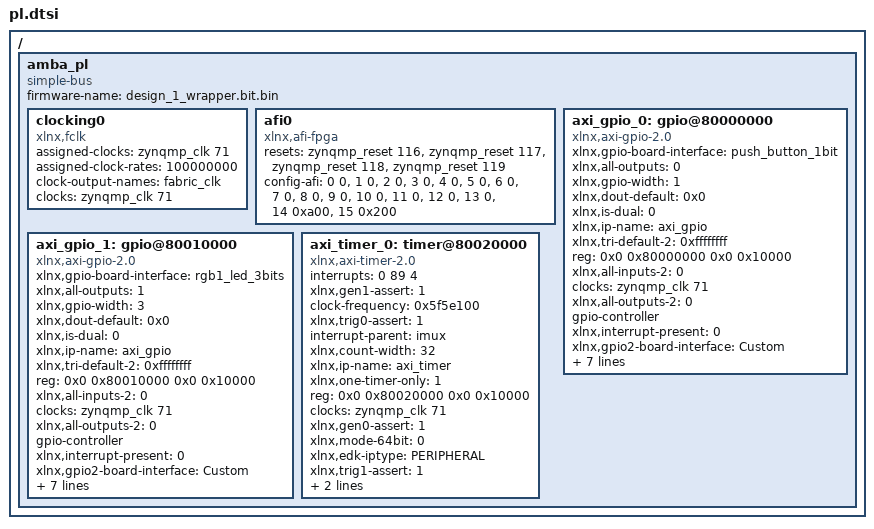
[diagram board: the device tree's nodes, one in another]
/ {
	amba_pl: amba_pl {
		ranges;
		compatible = "simple-bus";
		#address-cells = <2>;
		#size-cells = <2>;
		firmware-name = "design_1_wrapper.bit.bin";
		clocking0: clocking0 {
			compatible = "xlnx,fclk";
			status = "okay";
			assigned-clocks = <&zynqmp_clk 71>;
			assigned-clock-rates = <100000000>;
			#clock-cells = <0>;
			clock-output-names = "fabric_clk";
			clocks = <&zynqmp_clk 71>;
		};
		afi0: afi0 {
			status = "okay";
			compatible = "xlnx,afi-fpga";
			resets = <&zynqmp_reset 116>, <&zynqmp_reset 117>, <&zynqmp_reset 118>, <&zynqmp_reset 119>;
			config-afi = < 0 0>, <1 0>, <2 0>, <3 0>, <4 0>, <5 0>, <6 0>, <7 0>, <8 0>, <9 0>, <10 0>, <11 0>, <12 0>, <13 0>, <14 0xa00>, <15 0x200>;
		};
		axi_gpio_0: gpio@80000000 {
			xlnx,gpio-board-interface = "push_button_1bit";
			compatible = "xlnx,axi-gpio-2.0" , "xlnx,xps-gpio-1.00.a";
			xlnx,all-outputs = <0>;
			#gpio-cells = <2>;
			xlnx,gpio-width = <1>;
			xlnx,dout-default = <0x0>;
			xlnx,is-dual = <0>;
			xlnx,ip-name = "axi_gpio";
			xlnx,tri-default-2 = <0xffffffff>;
			reg = <0x0 0x80000000 0x0 0x10000>;
			xlnx,all-inputs-2 = <0>;
			clocks = <&zynqmp_clk 71>;
			xlnx,all-outputs-2 = <0>;
			gpio-controller;
			xlnx,interrupt-present = <0>;
			xlnx,gpio2-board-interface = "Custom";
			xlnx,edk-iptype = "PERIPHERAL";
			xlnx,dout-default-2 = <0x0>;
			status = "okay";
			xlnx,gpio2-width = <32>;
			clock-names = "s_axi_aclk";
			xlnx,use-board-flow;
			xlnx,tri-default = <0xffffffff>;
			xlnx,name = "axi_gpio_0";
			xlnx,all-inputs = <1>;
		};
		axi_gpio_1: gpio@80010000 {
			xlnx,gpio-board-interface = "rgb1_led_3bits";
			compatible = "xlnx,axi-gpio-2.0" , "xlnx,xps-gpio-1.00.a";
			xlnx,all-outputs = <1>;
			#gpio-cells = <2>;
			xlnx,gpio-width = <3>;
			xlnx,dout-default = <0x0>;
			xlnx,is-dual = <0>;
			xlnx,ip-name = "axi_gpio";
			xlnx,tri-default-2 = <0xffffffff>;
			reg = <0x0 0x80010000 0x0 0x10000>;
			xlnx,all-inputs-2 = <0>;
			clocks = <&zynqmp_clk 71>;
			xlnx,all-outputs-2 = <0>;
			gpio-controller;
			xlnx,interrupt-present = <0>;
			xlnx,gpio2-board-interface = "Custom";
			xlnx,edk-iptype = "PERIPHERAL";
			xlnx,dout-default-2 = <0x0>;
			status = "okay";
			xlnx,gpio2-width = <32>;
			clock-names = "s_axi_aclk";
			xlnx,use-board-flow;
			xlnx,tri-default = <0xffffffff>;
			xlnx,name = "axi_gpio_1";
			xlnx,all-inputs = <0>;
		};
		axi_timer_0: timer@80020000 {
			interrupts = < 0 89 4 >;
			compatible = "xlnx,axi-timer-2.0" , "xlnx,xps-timer-1.00.a";
			xlnx,gen1-assert = <1>;
			clock-frequency = <0x5f5e100>;
			xlnx,trig0-assert = <1>;
			interrupt-parent = <&imux>;
			xlnx,count-width = <32>;
			xlnx,ip-name = "axi_timer";
			xlnx,one-timer-only = <1>;
			reg = <0x0 0x80020000 0x0 0x10000>;
			clocks = <&zynqmp_clk 71>;
			xlnx,gen0-assert = <1>;
			xlnx,mode-64bit = <0>;
			xlnx,edk-iptype = "PERIPHERAL";
			status = "okay";
			xlnx,trig1-assert = <1>;
			clock-names = "s_axi_aclk";
			xlnx,enable-timer2 = <0>;
			interrupt-names = "interrupt";
			xlnx,name = "axi_timer_0";
		};
	};
};
